VERSION "created by canmatrix"

NS_ :

BS_:

BU_: User ADM_PC_LL25 ADM_PC_BC25 ADM_PC_BP25 ADM_PC_BI25

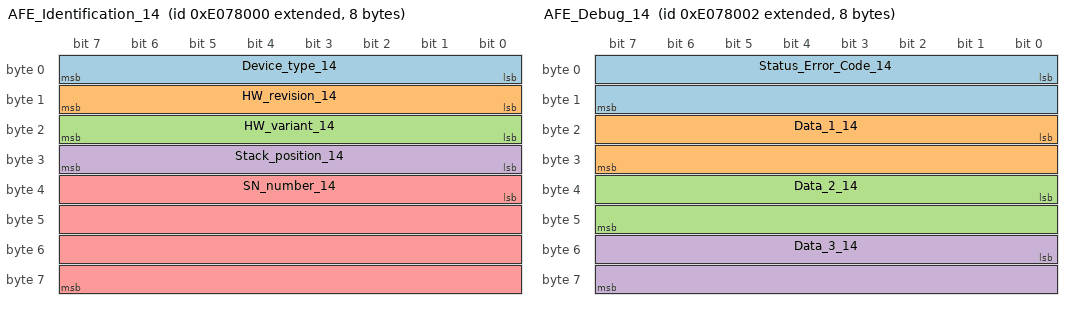
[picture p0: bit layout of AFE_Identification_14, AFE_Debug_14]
BO_ 2382856192 AFE_Identification_14: 8 ADM_PC_BP25
 SG_ Device_type_14 : 0|8@1+ (1,0) [0|255] "" Vector__XXX
 SG_ HW_revision_14 : 8|8@1+ (1,0) [0|255] "" Vector__XXX
 SG_ HW_variant_14 : 16|8@1+ (1,0) [0|255] "" Vector__XXX
 SG_ Stack_position_14 : 24|8@1+ (1,0) [0|255] "" Vector__XXX
 SG_ SN_number_14 : 32|32@1+ (1,0) [0|4294967295] "" Vector__XXX

BO_ 2382856193 AFE_FwInfo_14: 8 ADM_PC_BP25
 SG_ FW_info_mux_14 M : 56|8@1+ (1,0) [0|255] "" Vector__XXX
 SG_ FW_revision_0_14 m0 : 0|8@1+ (1,0) [0|255] "" Vector__XXX
 SG_ FW_revision_1_14 m0 : 8|8@1+ (1,0) [0|255] "" Vector__XXX
 SG_ FW_revision_2_14 m0 : 16|8@1+ (1,0) [0|255] "" Vector__XXX
 SG_ FW_revision_3_14 m0 : 24|8@1+ (1,0) [0|255] "" Vector__XXX
 SG_ FW_revision_4_14 m0 : 32|8@1+ (1,0) [0|255] "" Vector__XXX
 SG_ FW_revision_5_14 m0 : 40|8@1+ (1,0) [0|255] "" Vector__XXX
 SG_ FW_revision_6_14 m0 : 48|8@1+ (1,0) [0|255] "" Vector__XXX
 SG_ FW_revision_7_14 m1 : 0|8@1+ (1,0) [0|255] "" Vector__XXX
 SG_ FW_revision_8_14 m1 : 8|8@1+ (1,0) [0|255] "" Vector__XXX
 SG_ FW_revision_9_14 m1 : 16|8@1+ (1,0) [0|255] "" Vector__XXX
 SG_ FW_revision_10_14 m1 : 24|8@1+ (1,0) [0|255] "" Vector__XXX
 SG_ FW_revision_11_14 m1 : 32|8@1+ (1,0) [0|255] "" Vector__XXX
 SG_ FW_revision_12_14 m1 : 40|8@1+ (1,0) [0|255] "" Vector__XXX
 SG_ FW_revision_13_14 m1 : 48|8@1+ (1,0) [0|255] "" Vector__XXX
 SG_ FW_datecode_0_14 m2 : 0|8@1+ (1,0) [0|255] "" Vector__XXX
 SG_ FW_datecode_1_14 m2 : 8|8@1+ (1,0) [0|255] "" Vector__XXX
 SG_ FW_datecode_2_14 m2 : 16|8@1+ (1,0) [0|255] "" Vector__XXX
 SG_ FW_datecode_3_14 m2 : 24|8@1+ (1,0) [0|255] "" Vector__XXX
 SG_ FW_datecode_4_14 m2 : 32|8@1+ (1,0) [0|255] "" Vector__XXX
 SG_ FW_datecode_5_14 m2 : 40|8@1+ (1,0) [0|255] "" Vector__XXX
 SG_ FW_datecode_6_14 m2 : 48|8@1+ (1,0) [0|255] "" Vector__XXX
 SG_ FW_datecode_7_14 m3 : 0|8@1+ (1,0) [0|255] "" Vector__XXX
 SG_ FW_datecode_8_14 m3 : 8|8@1+ (1,0) [0|255] "" Vector__XXX
 SG_ FW_datecode_9_14 m3 : 16|8@1+ (1,0) [0|255] "" Vector__XXX
 SG_ FW_datecode_10_14 m3 : 24|8@1+ (1,0) [0|255] "" Vector__XXX
 SG_ FW_datecode_11_14 m3 : 32|8@1+ (1,0) [0|255] "" Vector__XXX
 SG_ FW_datecode_12_14 m3 : 40|8@1+ (1,0) [0|255] "" Vector__XXX
 SG_ FW_datecode_13_14 m3 : 48|8@1+ (1,0) [0|255] "" Vector__XXX

BO_ 2382856205 _AFE_Boot_FwInfo_14: 8 ADM_PC_BP25
 SG_ Boot_FW_info_mux_14 M : 56|8@1+ (1,0) [0|255] "" Vector__XXX
 SG_ FW_revision_0_14 m0 : 0|8@1+ (1,0) [0|255] "" Vector__XXX
 SG_ FW_revision_1_14 m0 : 8|8@1+ (1,0) [0|255] "" Vector__XXX
 SG_ FW_revision_2_14 m0 : 16|8@1+ (1,0) [0|255] "" Vector__XXX
 SG_ FW_revision_3_14 m0 : 24|8@1+ (1,0) [0|255] "" Vector__XXX
 SG_ FW_revision_4_14 m0 : 32|8@1+ (1,0) [0|255] "" Vector__XXX
 SG_ FW_revision_5_14 m0 : 40|8@1+ (1,0) [0|255] "" Vector__XXX
 SG_ FW_revision_6_14 m0 : 48|8@1+ (1,0) [0|255] "" Vector__XXX
 SG_ FW_revision_7_14 m1 : 0|8@1+ (1,0) [0|255] "" Vector__XXX
 SG_ FW_revision_8_14 m1 : 8|8@1+ (1,0) [0|255] "" Vector__XXX
 SG_ FW_revision_9_14 m1 : 16|8@1+ (1,0) [0|255] "" Vector__XXX
 SG_ FW_revision_10_14 m1 : 24|8@1+ (1,0) [0|255] "" Vector__XXX
 SG_ FW_revision_11_14 m1 : 32|8@1+ (1,0) [0|255] "" Vector__XXX
 SG_ FW_revision_12_14 m1 : 40|8@1+ (1,0) [0|255] "" Vector__XXX
 SG_ FW_revision_13_14 m1 : 48|8@1+ (1,0) [0|255] "" Vector__XXX
 SG_ FW_datecode_0_14 m2 : 0|8@1+ (1,0) [0|255] "" Vector__XXX
 SG_ FW_datecode_1_14 m2 : 8|8@1+ (1,0) [0|255] "" Vector__XXX
 SG_ FW_datecode_2_14 m2 : 16|8@1+ (1,0) [0|255] "" Vector__XXX
 SG_ FW_datecode_3_14 m2 : 24|8@1+ (1,0) [0|255] "" Vector__XXX
 SG_ FW_datecode_4_14 m2 : 32|8@1+ (1,0) [0|255] "" Vector__XXX
 SG_ FW_datecode_5_14 m2 : 40|8@1+ (1,0) [0|255] "" Vector__XXX
 SG_ FW_datecode_6_14 m2 : 48|8@1+ (1,0) [0|255] "" Vector__XXX
 SG_ FW_datecode_7_14 m3 : 0|8@1+ (1,0) [0|255] "" Vector__XXX
 SG_ FW_datecode_8_14 m3 : 8|8@1+ (1,0) [0|255] "" Vector__XXX
 SG_ FW_datecode_9_14 m3 : 16|8@1+ (1,0) [0|255] "" Vector__XXX
 SG_ FW_datecode_10_14 m3 : 24|8@1+ (1,0) [0|255] "" Vector__XXX
 SG_ FW_datecode_11_14 m3 : 32|8@1+ (1,0) [0|255] "" Vector__XXX
 SG_ FW_datecode_12_14 m3 : 40|8@1+ (1,0) [0|255] "" Vector__XXX
 SG_ FW_datecode_13_14 m3 : 48|8@1+ (1,0) [0|255] "" Vector__XXX

BO_ 2382856194 AFE_Debug_14: 8 ADM_PC_BP25
 SG_ Status_Error_Code_14 : 0|16@1+ (1,0) [0|65535] "" Vector__XXX
 SG_ Data_1_14 : 16|16@1+ (1,0) [0|65535] "" Vector__XXX
 SG_ Data_2_14 : 32|16@1+ (1,0) [0|65535] "" Vector__XXX
 SG_ Data_3_14 : 48|16@1+ (1,0) [0|65535] "" Vector__XXX

BO_ 2382856199 AFE_Status_14: 8 ADM_PC_BP25
 SG_ Running_14 : 0|1@1+ (1,0) [0|1] "" Vector__XXX
 SG_ PWM_14 : 1|1@1+ (1,0) [0|1] "" Vector__XXX
 SG_ Current_dc_loop_mode_14 : 2|1@1+ (1,0) [0|1] "" Vector__XXX
 SG_ Current_ac_loop_mode_14 : 3|1@1+ (1,0) [0|1] "" Vector__XXX
 SG_ Buck_14 : 5|1@1+ (1,0) [0|1] "" Vector__XXX
 SG_ Boost_14 : 6|1@1+ (1,0) [0|1] "" Vector__XXX
 SG_ Precharge_dc_buck_mode_14 : 7|1@1+ (1,0) [0|1] "" Vector__XXX
 SG_ Precharge_dc_boost_mode_14 : 8|1@1+ (1,0) [0|1] "" Vector__XXX
 SG_ Rectifier_3ph_14 : 9|1@1+ (1,0) [0|1] "" Vector__XXX
 SG_ Stack_mode_14 : 10|1@1+ (1,0) [0|1] "" Vector__XXX
 SG_ Master_14 : 11|1@1+ (1,0) [0|1] "" Vector__XXX
 SG_ Slave_14 : 12|1@1+ (1,0) [0|1] "" Vector__XXX
 SG_ Inverter_1ph_14 : 13|1@1+ (1,0) [0|1] "" Vector__XXX
 SG_ Boost_Neutral_14 : 14|1@1+ (1,0) [0|1] "" Vector__XXX
 SG_ Rectifier_1ph_14 : 15|1@1+ (1,0) [0|1] "" Vector__XXX
 SG_ Inverter_3ph_14 : 16|1@1+ (1,0) [0|1] "" Vector__XXX
 SG_ Ready_14 : 17|1@1+ (1,0) [0|1] "" Vector__XXX
 SG_ Inverter_1ph_Sync_14 : 18|1@1+ (1,0) [0|1] "" Vector__XXX
 SG_ Neutral_14 : 19|1@1+ (1,0) [0|1] "" Vector__XXX
 SG_ Rectifier_1ph_Buck_14 : 20|1@1+ (1,0) [0|1] "" Vector__XXX
 SG_ Inverter_1ph_Boost_14 : 21|1@1+ (1,0) [0|1] "" Vector__XXX
 SG_ Rectifier_distributed_14 : 22|1@1+ (1,0) [0|1] "" Vector__XXX
 SG_ MPPT_buck_14 : 23|1@1+ (1,0) [0|1] "" Vector__XXX
 SG_ MPPT_boost_14 : 24|1@1+ (1,0) [0|1] "" Vector__XXX
 SG_ Buck_2p_float_14 : 25|1@1+ (1,0) [0|1] "" Vector__XXX
 SG_ Inverter_1ph_Distributed_14 : 26|1@1+ (1,0) [0|1] "" Vector__XXX

BO_ 2382856198 AFE_Faults_14: 3 ADM_PC_BP25
 SG_ Protection_trip_internal_14 : 0|1@1+ (1,0) [0|1] "" Vector__XXX
 SG_ Protection_trip_external_14 : 1|1@1+ (1,0) [0|1] "" Vector__XXX
 SG_ Phase_U_overcurrent_14 : 2|1@1+ (1,0) [0|1] "" Vector__XXX
 SG_ Phase_U_overvoltage_14 : 3|1@1+ (1,0) [0|1] "" Vector__XXX
 SG_ Phase_U_undervoltage_14 : 4|1@1+ (1,0) [0|1] "" Vector__XXX
 SG_ Phase_V_overvoltage_14 : 5|1@1+ (1,0) [0|1] "" Vector__XXX
 SG_ Phase_V_undervoltage_14 : 6|1@1+ (1,0) [0|1] "" Vector__XXX
 SG_ Phase_V_overcurrent_14 : 7|1@1+ (1,0) [0|1] "" Vector__XXX
 SG_ Phase_W_overvoltage_14 : 8|1@1+ (1,0) [0|1] "" Vector__XXX
 SG_ Phase_W_undervoltage_14 : 9|1@1+ (1,0) [0|1] "" Vector__XXX
 SG_ Phase_W_overcurrent_14 : 10|1@1+ (1,0) [0|1] "" Vector__XXX
 SG_ DC_undervoltage_14 : 11|1@1+ (1,0) [0|1] "" Vector__XXX
 SG_ DC_overvoltage_14 : 12|1@1+ (1,0) [0|1] "" Vector__XXX
 SG_ MOSFET_overtemperature_14 : 13|1@1+ (1,0) [0|1] "" Vector__XXX
 SG_ Inductor_overtemperature_14 : 14|1@1+ (1,0) [0|1] "" Vector__XXX
 SG_ Keep_Alive_not_served_14 : 15|1@1+ (1,0) [0|1] "" Vector__XXX
 SG_ PLL_not_locked_14 : 16|1@1+ (1,0) [0|1] "" Vector__XXX
 SG_ NFO_14 : 20|1@1+ (1,0) [0|1] "" Vector__XXX
 SG_ Measurement_system_failure_14 : 21|1@1+ (1,0) [0|1] "" Vector__XXX
 SG_ EEPROM_failure_14 : 22|1@1+ (1,0) [0|1] "" Vector__XXX
 SG_ System_14 : 23|1@1+ (1,0) [0|1] "" Vector__XXX

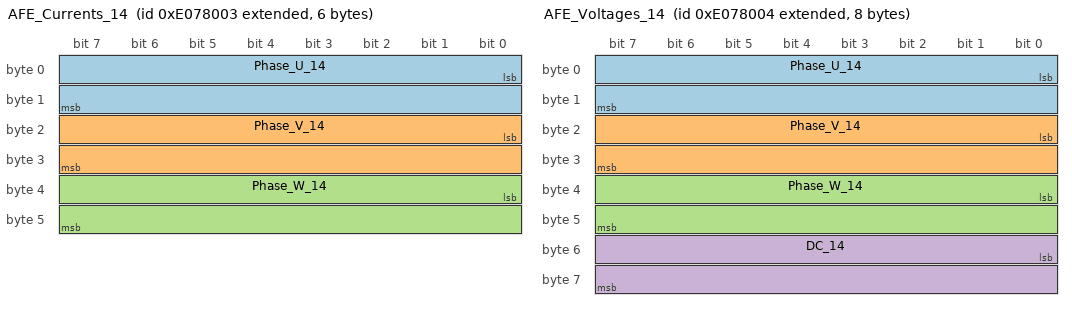
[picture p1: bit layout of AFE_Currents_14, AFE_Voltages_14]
BO_ 2382856195 AFE_Currents_14: 6 ADM_PC_BP25
 SG_ Phase_U_14 : 0|16@1- (0.01,0) [-327.68|327.67] "A" Vector__XXX
 SG_ Phase_V_14 : 16|16@1- (0.01,0) [-327.68|327.67] "A" Vector__XXX
 SG_ Phase_W_14 : 32|16@1- (0.01,0) [-327.68|327.67] "A" Vector__XXX

BO_ 2382856208 AFE_DC_Bus_current_14: 2 ADM_PC_BP25
 SG_ Bus_current_14 : 0|16@1- (0.01,0) [-327.68|327.67] "A" Vector__XXX

BO_ 2382856206 _AFE_Broadcast_14: 8 ADM_PC_BP25
 SG_ Diagnostics_Index_14 M : 56|8@1+ (1,0) [0|255] "" Vector__XXX
 SG_ Phase_U_14 m1 : 8|16@1- (0.01,0) [-327.68|327.67] "A" ADM_PC_BP25
 SG_ Phase_V_14 m1 : 24|16@1- (0.01,0) [-327.68|327.67] "A" ADM_PC_BP25
 SG_ Phase_W_14 m1 : 40|16@1- (0.01,0) [-327.68|327.67] "A" ADM_PC_BP25
 SG_ Stack_position_14 : 0|5@1+ (1,0) [0|31] "" ADM_PC_BP25
 SG_ Group_ID_14 : 5|3@1+ (1,0) [0|7] "" ADM_PC_BP25

BO_ 2382856196 AFE_Voltages_14: 8 ADM_PC_BP25
 SG_ Phase_U_14 : 0|16@1- (0.1,0) [-3276.8|3276.7] "V" Vector__XXX
 SG_ Phase_V_14 : 16|16@1- (0.1,0) [-3276.8|3276.7] "V" Vector__XXX
 SG_ Phase_W_14 : 32|16@1- (0.1,0) [-3276.8|3276.7] "V" Vector__XXX
 SG_ DC_14 : 48|16@1- (0.1,0) [-3276.8|3276.7] "V" Vector__XXX

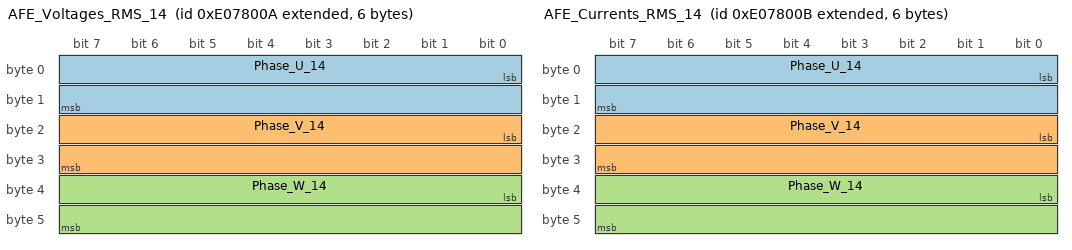
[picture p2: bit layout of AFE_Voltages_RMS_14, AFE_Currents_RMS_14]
BO_ 2382856202 AFE_Voltages_RMS_14: 6 ADM_PC_BP25
 SG_ Phase_U_14 : 0|16@1+ (0.1,0) [0|6553.5] "V" Vector__XXX
 SG_ Phase_V_14 : 16|16@1+ (0.1,0) [0|6553.5] "V" Vector__XXX
 SG_ Phase_W_14 : 32|16@1+ (0.1,0) [0|6553.5] "V" Vector__XXX

BO_ 2382856203 AFE_Currents_RMS_14: 6 ADM_PC_BP25
 SG_ Phase_U_14 : 0|16@1+ (0.01,0) [0.00|655.35] "A" Vector__XXX
 SG_ Phase_V_14 : 16|16@1+ (0.01,0) [0.00|655.35] "A" Vector__XXX
 SG_ Phase_W_14 : 32|16@1+ (0.01,0) [0.00|655.35] "A" Vector__XXX

BO_ 2382856204 AFE_Mains_14: 4 ADM_PC_BP25
 SG_ Frequency_14 : 0|16@1+ (0.01,0) [0.00|655.35] "Hz" Vector__XXX
 SG_ Phase_14 : 16|16@1- (0.1,0) [-3276.8|3276.7] "Deg." Vector__XXX

BO_ 2382856197 AFE_Temperatures_14: 4 ADM_PC_BP25
 SG_ Temp_Bridge_14 : 0|16@1- (0.01,0) [-327.68|327.67] "°C" Vector__XXX
 SG_ Temp_Inductors_14 : 16|16@1- (0.01,0) [-327.68|327.67] "°C" Vector__XXX

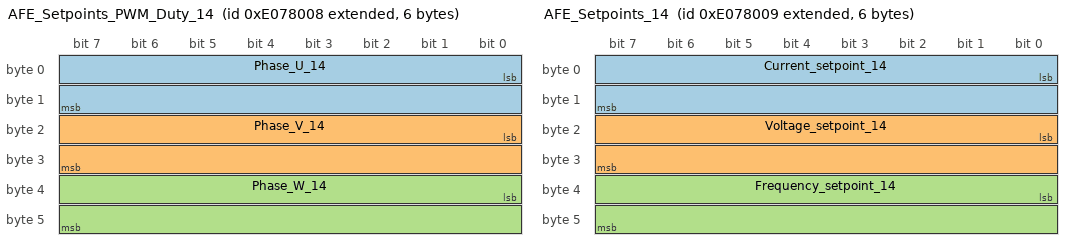
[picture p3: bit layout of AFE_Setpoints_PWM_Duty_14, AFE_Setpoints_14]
BO_ 2382856200 AFE_Setpoints_PWM_Duty_14: 6 ADM_PC_BP25
 SG_ Phase_U_14 : 0|16@1+ (0.001525902,0) [0E-009|99.999987570] "%" Vector__XXX
 SG_ Phase_V_14 : 16|16@1+ (0.001525902,0) [0E-009|99.999987570] "%" Vector__XXX
 SG_ Phase_W_14 : 32|16@1+ (0.001525902,0) [0E-009|99.999987570] "%" Vector__XXX

BO_ 2382856201 AFE_Setpoints_14: 6 ADM_PC_BP25
 SG_ Current_setpoint_14 : 0|16@1- (0.01,0) [-327.68|327.67] "A" Vector__XXX
 SG_ Voltage_setpoint_14 : 16|16@1+ (0.1,0) [0|6553.5] "V" Vector__XXX
 SG_ Frequency_setpoint_14 : 32|16@1+ (0.01,0) [0.00|655.35] "Hz" Vector__XXX

BO_ 2382823520 AFE_Keep_Alive_14: 1 User
 SG_ Keep_Alive_Enable_14 : 0|1@1+ (1,0) [0|1] "" ADM_PC_BP25

BO_ 2382823488 AFE_Mode_Control_14: 8 User
 SG_ Converter_ON_14 : 0|1@1+ (1,0) [0|1] "" ADM_PC_BP25
 SG_ PWM_ON_14 : 1|1@1+ (1,0) [0|1] "" ADM_PC_BP25
 SG_ DC_Current_feedback_ON_14 : 2|1@1+ (1,0) [0|1] "" ADM_PC_BP25
 SG_ AC_Current_feedback_ON_14 : 3|1@1+ (1,0) [0|1] "" ADM_PC_BP25
 SG_ Buck_ON_14 : 5|1@1+ (1,0) [0|1] "" ADM_PC_BP25
 SG_ Boost_ON_14 : 6|1@1+ (1,0) [0|1] "" ADM_PC_BP25
 SG_ Rectifier_3ph_ON_14 : 9|1@1+ (1,0) [0|1] "" ADM_PC_BP25
 SG_ Inverter_1ph_ON_14 : 10|1@1+ (1,0) [0|1] "" ADM_PC_BP25
 SG_ Rectifier_1ph_ON_14 : 11|1@1+ (1,0) [0|1] "" ADM_PC_BP25
 SG_ Boost_Neutral_ON_14 : 12|1@1+ (1,0) [0|1] "" ADM_PC_BP25
 SG_ Inverter_3ph_ON_14 : 13|1@1+ (1,0) [0|1] "" ADM_PC_BP25
 SG_ Inverter_1ph_Sync_ON_14 : 14|1@1+ (1,0) [0|1] "" ADM_PC_BP25
 SG_ Neutral_ON_14 : 15|1@1+ (1,0) [0|1] "" ADM_PC_BP25
 SG_ Rectifier_1ph_Buck_ON_14 : 16|1@1+ (1,0) [0|1] "" ADM_PC_BP25
 SG_ Inverter_1ph_Boost_ON_14 : 17|1@1+ (1,0) [0|1] "" ADM_PC_BP25
 SG_ Rectifier_Distributed_ON_14 : 18|1@1+ (1,0) [0|1] "" ADM_PC_BP25
 SG_ MPPT_buck_ON_14 : 19|1@1+ (1,0) [0|1] "" ADM_PC_BP25
 SG_ MPPT_boost_ON_14 : 20|1@1+ (1,0) [0|1] "" ADM_PC_BP25
 SG_ Buck_2p_float_ON_14 : 21|1@1+ (1,0) [0|1] "" ADM_PC_BP25
 SG_ Inverter_1ph_Distributed_ON_14 : 22|1@1+ (1,0) [0|1] "" ADM_PC_BP25

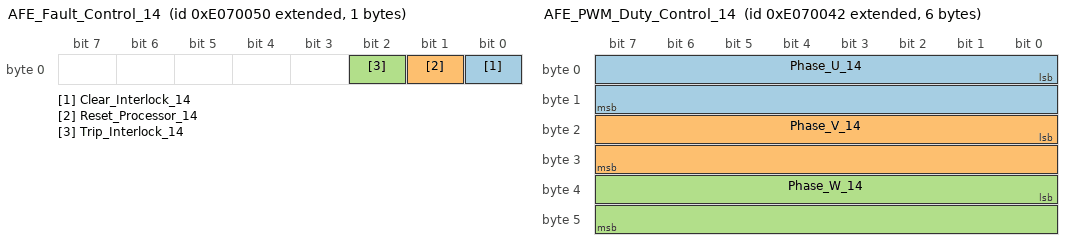
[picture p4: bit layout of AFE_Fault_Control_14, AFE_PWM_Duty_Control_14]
BO_ 2382823504 AFE_Fault_Control_14: 1 User
 SG_ Clear_Interlock_14 : 0|1@1+ (1,0) [0|1] "" ADM_PC_BP25
 SG_ Reset_Processor_14 : 1|1@1+ (1,0) [0|1] "" ADM_PC_BP25
 SG_ Trip_Interlock_14 : 2|1@1+ (1,0) [0|1] "" ADM_PC_BP25

BO_ 2382823489 AFE_Reactive_Current_Setpoint_Co: 2 User
 SG_ Reactive_current_setpoint_14 : 0|16@1- (0.01,0) [-150|150] "A" ADM_PC_BP25

BO_ 2382823490 AFE_PWM_Duty_Control_14: 6 User
 SG_ Phase_U_14 : 0|16@1+ (0.001525902,0) [0E-009|99.999987570] "%" ADM_PC_BP25
 SG_ Phase_V_14 : 16|16@1+ (0.001525902,0) [0E-009|99.999987570] "%" ADM_PC_BP25
 SG_ Phase_W_14 : 32|16@1+ (0.001525902,0) [0E-009|99.999987570] "%" ADM_PC_BP25

BO_ 2382823491 AFE_Current_Setpoint_Control_14: 2 User
 SG_ Current_setpoint_14 : 0|16@1- (0.01,0) [-150|150] "A" ADM_PC_BP25

BO_ 2382823492 AFE_Voltage_Setpoint_Control_14: 2 User
 SG_ Voltage_setpoint_14 : 0|16@1+ (0.1,0) [0|1500] "V" ADM_PC_BP25

BO_ 2382823496 AFE_Frequency_Setpoint_Control_1: 2 User
 SG_ Frequency_setpoint_14 : 0|16@1+ (0.01,0) [40|70] "Hz" ADM_PC_BP25

BO_ 2382823497 AFE_Phase_Setpoint_Control_14: 2 User
 SG_ Phase_setpoint_14 : 0|16@1+ (1,0) [0|360] "deg" ADM_PC_BP25

BO_ 2382823536 AFE_Rectifier_Setpoint_Control_1: 8 User
 SG_ Voltage_setpoint_2_14 : 0|16@1+ (0.1,0) [0|1500] "V" ADM_PC_BP25
 SG_ Current_setpoint_2_14 : 16|16@1- (0.01,0) [-150|150] "A" ADM_PC_BP25

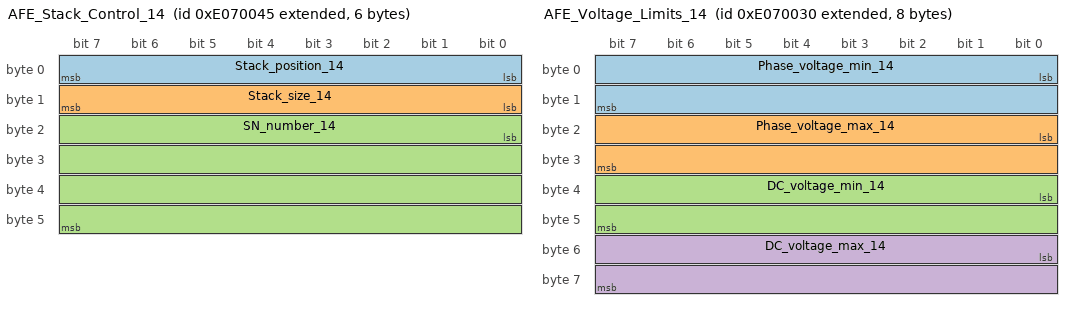
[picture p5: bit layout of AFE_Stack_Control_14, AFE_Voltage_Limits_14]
BO_ 2382823493 AFE_Stack_Control_14: 6 User
 SG_ Stack_position_14 : 0|8@1+ (1,0) [0|255] "" ADM_PC_BP25
 SG_ Stack_size_14 : 8|8@1+ (1,0) [0|255] "" ADM_PC_BP25
 SG_ SN_number_14 : 16|32@1+ (1,0) [0|4294967295] "" ADM_PC_BP25

BO_ 2382823472 AFE_Voltage_Limits_14: 8 User
 SG_ Phase_voltage_min_14 : 0|16@1- (0.1,0) [0|3276.7] "V" ADM_PC_BP25
 SG_ Phase_voltage_max_14 : 16|16@1- (0.1,0) [-3276.8|850] "V" ADM_PC_BP25
 SG_ DC_voltage_min_14 : 32|16@1- (0.1,0) [0|3276.7] "V" ADM_PC_BP25
 SG_ DC_voltage_max_14 : 48|16@1- (0.1,0) [-3276.8|850] "V" ADM_PC_BP25

BO_ 2382823473 AFE_Current_Limits_14: 4 User
 SG_ Phase_current_min_14 : 0|16@1- (0.01,0) [-60|60] "A" ADM_PC_BP25
 SG_ Phase_current_max_14 : 16|16@1- (0.01,0) [-60|60] "A" ADM_PC_BP25

BO_ 2382823500 AFE_Group_Control_14: 1 User
 SG_ Group_ID_14 : 0|8@1+ (1,0) [0|255] "" ADM_PC_BP25

BO_ 2382856207 AFE_Group_Info_14: 1 ADM_PC_BP25
 SG_ Group_ID_14 : 0|8@1+ (1,0) [0|255] "" Vector__XXX

BO_ 2382823521 AFE_System_Flags_Control_14: 8 User
 SG_ Factory_mode_14 : 0|1@1+ (1,0) [0|1] "" ADM_PC_BP25
 SG_ Silent_CAN_mode_14 : 1|1@1+ (1,0) [0|1] "" ADM_PC_BP25

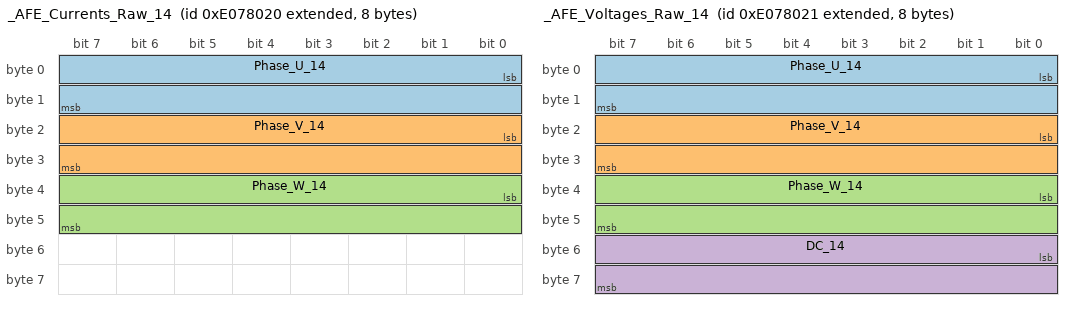
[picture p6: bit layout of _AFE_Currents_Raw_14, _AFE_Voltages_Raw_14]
BO_ 2382856224 _AFE_Currents_Raw_14: 8 ADM_PC_BP25
 SG_ Phase_U_14 : 0|16@1- (1,0) [-32768|32767] "" Vector__XXX
 SG_ Phase_V_14 : 16|16@1- (1,0) [-32768|32767] "" Vector__XXX
 SG_ Phase_W_14 : 32|16@1- (1,0) [-32768|32767] "" Vector__XXX

BO_ 2382856225 _AFE_Voltages_Raw_14: 8 ADM_PC_BP25
 SG_ Phase_U_14 : 0|16@1- (1,0) [-32768|32767] "" Vector__XXX
 SG_ Phase_V_14 : 16|16@1- (1,0) [-32768|32767] "" Vector__XXX
 SG_ Phase_W_14 : 32|16@1- (1,0) [-32768|32767] "" Vector__XXX
 SG_ DC_14 : 48|16@1- (1,0) [-32768|32767] "" Vector__XXX

BO_ 2382823498 _AFE_ADC_Calibration_Mode_14: 1 User
 SG_ Calibration_Index_14 M : 2|5@1+ (1,0) [0|31] "" Vector__XXX
 SG_ Current_U_14 m1 : 0|2@1+ (1,0) [0|3] "" ADM_PC_BP25
 SG_ Current_V_14 m2 : 0|2@1+ (1,0) [0|3] "" ADM_PC_BP25
 SG_ Current_W_14 m3 : 0|2@1+ (1,0) [0|3] "" ADM_PC_BP25
 SG_ Voltage_U_14 m4 : 0|2@1+ (1,0) [0|3] "" ADM_PC_BP25
 SG_ Voltage_V_14 m5 : 0|2@1+ (1,0) [0|3] "" ADM_PC_BP25
 SG_ Voltage_W_14 m6 : 0|2@1+ (1,0) [0|3] "" ADM_PC_BP25
 SG_ Voltage_DC_14 m7 : 0|2@1+ (1,0) [0|3] "" ADM_PC_BP25
 SG_ start_14 : 7|1@1+ (1,0) [0|1] "" ADM_PC_BP25

BO_ 2382823499 _AFE_ADC_Calibration_Setpoint_14: 3 User
 SG_ Calibration_Index_14 M : 16|5@1+ (1,0) [0|31] "" Vector__XXX
 SG_ Current_U_14 m1 : 0|16@1- (0.01,0) [-100|100] "A" ADM_PC_BP25
 SG_ Current_V_14 m2 : 0|16@1- (0.01,0) [-100|100] "A" ADM_PC_BP25
 SG_ Current_W_14 m3 : 0|16@1- (0.01,0) [-100|100] "A" ADM_PC_BP25
 SG_ Voltage_U_14 m4 : 0|16@1+ (0.1,0) [0|1500] "V" ADM_PC_BP25
 SG_ Voltage_V_14 m5 : 0|16@1+ (0.1,0) [0|1500] "V" ADM_PC_BP25
 SG_ Voltage_W_14 m6 : 0|16@1+ (0.1,0) [0|1500] "V" ADM_PC_BP25
 SG_ Voltage_DC_14 m7 : 0|16@1+ (0.1,0) [0|1500] "V" ADM_PC_BP25
 SG_ point_14 : 21|3@1+ (1,0) [0|7] "" ADM_PC_BP25

BO_ 2382823494 _AFE_Calibration_Offset_Update_1: 6 User
 SG_ Calibration_Index_14 M : 16|16@1+ (1,0) [0|65535] "" Vector__XXX
 SG_ Current_U_14 m0 : 0|16@1- (1,0) [-32768|32767] "ADC Counts" ADM_PC_BP25
 SG_ Current_V_14 m1 : 0|16@1- (1,0) [-32768|32767] "ADC Counts" ADM_PC_BP25
 SG_ Current_W_14 m2 : 0|16@1- (1,0) [-32768|32767] "ADC Counts" ADM_PC_BP25
 SG_ Voltage_U_14 m3 : 0|16@1- (1,0) [-32768|32767] "ADC Counts" ADM_PC_BP25
 SG_ Voltage_V_14 m4 : 0|16@1- (1,0) [-32768|32767] "ADC Counts" ADM_PC_BP25
 SG_ Voltage_W_14 m5 : 0|16@1- (1,0) [-32768|32767] "ADC Counts" ADM_PC_BP25
 SG_ Voltage_DC_14 m6 : 0|16@1- (1,0) [-32768|32767] "ADC Counts" ADM_PC_BP25
 SG_ CRC_14 : 32|16@1+ (1,0) [0|65535] "-" ADM_PC_BP25

BO_ 2382823495 _AFE_Calibration_Scale_Update_14: 6 User
 SG_ Calibration_Index_14 M : 16|16@1+ (1,0) [0|65535] "" Vector__XXX
 SG_ Current_U_14 m0 : 0|16@1- (0.0000152587890625,0) [-0.5000000000000000|0.4999847412109375] "scale = 1.0 + value" ADM_PC_BP25
 SG_ Current_V_14 m1 : 0|16@1- (0.0000152587890625,0) [-0.5000000000000000|0.4999847412109375] "scale = 1.0 + value" ADM_PC_BP25
 SG_ Current_W_14 m2 : 0|16@1- (0.0000152587890625,0) [-0.5000000000000000|0.4999847412109375] "scale = 1.0 + value" ADM_PC_BP25
 SG_ Voltage_U_14 m3 : 0|16@1- (0.0000152587890625,0) [-0.5000000000000000|0.4999847412109375] "scale = 1.0 + value" ADM_PC_BP25
 SG_ Voltage_V_14 m4 : 0|16@1- (0.0000152587890625,0) [-0.5000000000000000|0.4999847412109375] "scale = 1.0 + value" ADM_PC_BP25
 SG_ Voltage_W_14 m5 : 0|16@1- (0.0000152587890625,0) [-0.5000000000000000|0.4999847412109375] "scale = 1.0 + value" ADM_PC_BP25
 SG_ Voltage_DC_14 m6 : 0|16@1- (0.0000152587890625,0) [-0.5000000000000000|0.4999847412109375] "scale = 1.0 + value" ADM_PC_BP25
 SG_ CRC_14 : 32|16@1+ (1,0) [0|65535] "-" ADM_PC_BP25

BO_ 2382856273 _AFE_Calibration_Adc_Scale_14: 6 ADM_PC_BP25
 SG_ Adc_Index_14 M : 32|16@1+ (1,0) [0|65535] "" Vector__XXX
 SG_ Current_U_14 m0 : 0|32@1+ (1,0) [0|4294967295] "1 / adc_bins" User
 SG_ Current_V_14 m1 : 0|32@1+ (1,0) [0|4294967295] "1 / adc_bins" User
 SG_ Current_W_14 m2 : 0|32@1+ (1,0) [0|4294967295] "1 / adc_bins" User
 SG_ Voltage_U_14 m3 : 0|32@1+ (1,0) [0|4294967295] "1 / adc_bins" User
 SG_ Voltage_V_14 m4 : 0|32@1+ (1,0) [0|4294967295] "1 / adc_bins" User
 SG_ Voltage_W_14 m5 : 0|32@1+ (1,0) [0|4294967295] "1 / adc_bins" User
 SG_ Voltage_DC_14 m6 : 0|32@1+ (1,0) [0|4294967295] "1 / adc_bins" User

BO_ 2382856274 _AFE_Calibration_Adc_Fs_14: 6 ADM_PC_BP25
 SG_ Adc_Index_14 M : 32|16@1+ (1,0) [0|65535] "" Vector__XXX
 SG_ Current_U_14 m0 : 0|32@1+ (1,0) [0|4294967295] "Fullscale" User
 SG_ Current_V_14 m1 : 0|32@1+ (1,0) [0|4294967295] "Fullscale" User
 SG_ Current_W_14 m2 : 0|32@1+ (1,0) [0|4294967295] "Fullscale" User
 SG_ Voltage_U_14 m3 : 0|32@1+ (1,0) [0|4294967295] "Fullscale" User
 SG_ Voltage_V_14 m4 : 0|32@1+ (1,0) [0|4294967295] "Fullscale" User
 SG_ Voltage_W_14 m5 : 0|32@1+ (1,0) [0|4294967295] "Fullscale" User
 SG_ Voltage_DC_14 m6 : 0|32@1+ (1,0) [0|4294967295] "Fullscale" User

BO_ 2382856275 _AFE_Calibration_Adc_Offset_14: 4 ADM_PC_BP25
 SG_ Adc_Index_14 M : 16|16@1+ (1,0) [0|65535] "" Vector__XXX
 SG_ Current_U_14 m0 : 0|16@1- (1,0) [-32768|32767] "-" User
 SG_ Current_V_14 m1 : 0|16@1- (1,0) [-32768|32767] "-" User
 SG_ Current_W_14 m2 : 0|16@1- (1,0) [-32768|32767] "-" User
 SG_ Voltage_U_14 m3 : 0|16@1- (1,0) [-32768|32767] "-" User
 SG_ Voltage_V_14 m4 : 0|16@1- (1,0) [-32768|32767] "-" User
 SG_ Voltage_W_14 m5 : 0|16@1- (1,0) [-32768|32767] "-" User
 SG_ Voltage_DC_14 m6 : 0|16@1- (1,0) [-32768|32767] "-" User

BO_ 2382856276 _AFE_Calibration_Adc_Gain_14: 4 ADM_PC_BP25
 SG_ Adc_Index_14 M : 16|16@1+ (1,0) [0|65535] "" Vector__XXX
 SG_ Current_U_14 m0 : 0|16@1- (1,0) [-32768|32767] "-" User
 SG_ Current_V_14 m1 : 0|16@1- (1,0) [-32768|32767] "-" User
 SG_ Current_W_14 m2 : 0|16@1- (1,0) [-32768|32767] "-" User
 SG_ Voltage_U_14 m3 : 0|16@1- (1,0) [-32768|32767] "-" User
 SG_ Voltage_V_14 m4 : 0|16@1- (1,0) [-32768|32767] "-" User
 SG_ Voltage_W_14 m5 : 0|16@1- (1,0) [-32768|32767] "-" User
 SG_ Voltage_DC_14 m6 : 0|16@1- (1,0) [-32768|32767] "-" User

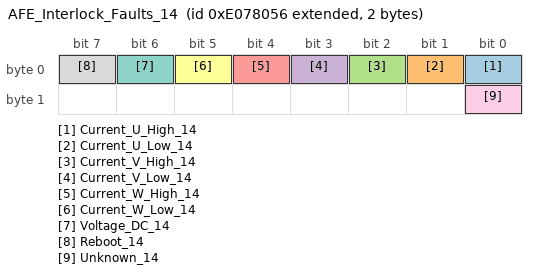
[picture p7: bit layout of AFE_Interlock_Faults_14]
BO_ 2382856278 AFE_Interlock_Faults_14: 2 ADM_PC_BP25
 SG_ Current_U_High_14 : 0|1@1+ (1,0) [0|1] "" Vector__XXX
 SG_ Current_U_Low_14 : 1|1@1+ (1,0) [0|1] "" Vector__XXX
 SG_ Current_V_High_14 : 2|1@1+ (1,0) [0|1] "" Vector__XXX
 SG_ Current_V_Low_14 : 3|1@1+ (1,0) [0|1] "" Vector__XXX
 SG_ Current_W_High_14 : 4|1@1+ (1,0) [0|1] "" Vector__XXX
 SG_ Current_W_Low_14 : 5|1@1+ (1,0) [0|1] "" Vector__XXX
 SG_ Voltage_DC_14 : 6|1@1+ (1,0) [0|1] "" Vector__XXX
 SG_ Reboot_14 : 7|1@1+ (1,0) [0|1] "" Vector__XXX
 SG_ Unknown_14 : 8|1@1+ (1,0) [0|1] "" Vector__XXX

BO_TX_BU_ 2382823488 : User,ADM_PC_LL25,ADM_PC_BC25,ADM_PC_BI25;
BO_TX_BU_ 2382823491 : User,ADM_PC_LL25,ADM_PC_BC25,ADM_PC_BI25;
BO_TX_BU_ 2382823492 : User,ADM_PC_LL25,ADM_PC_BC25,ADM_PC_BI25;
CM_ BO_ 2382856192  "Identification of the device";
CM_ BO_ 2382856193  "Git revision of the DSP firmware";
CM_ BO_ 2382856205  "Git revision of the bootloader firmware.";
CM_ BO_ 2382856194  "Values for debugging of HW/SW problems";
CM_ BO_ 2382856199  "Status bitfield";
CM_ BO_ 2382856198  "Fault bitfield";
CM_ BO_ 2382856195  "Current of phases U, V, W";
CM_ BO_ 2382856208  "Current of of the DC Bus";
CM_ BO_ 2382856206  "All AFEs will listen to this message";
CM_ BO_ 2382856203  "RMS Current of phases U, V, W";
CM_ BO_ 2382856204  "Three-Phase mains health (frequency, phase...)";
CM_ BO_ 2382856197  "Readouts of the module temperature sensors";
CM_ BO_ 2382856200  "Setpoints";
CM_ BO_ 2382856201  "Setpoints";
CM_ BO_ 2382823520  "Keep alive ping message. ";
CM_ BO_ 2382823488  "Operation Mode control: sets the converter operation mode";
CM_ BO_ 2382823504  "Fault Control: actions to clear faults and reset the system";
CM_ BO_ 2382823489  "Reactive power setpoint control.";
CM_ BO_ 2382823490  "PWM duty cycle control";
CM_ BO_ 2382823491  "Current setpoint control";
CM_ BO_ 2382823492  "Voltage setpoint control";
CM_ BO_ 2382823496  "Frequency setpoint control";
CM_ BO_ 2382823497  "Phase setpoint control";
CM_ BO_ 2382823536  "Additional voltage and current setpoints in single-phase rectifier and inverter control modes.";
CM_ BO_ 2382823493  "PFC stack control";
CM_ BO_ 2382823472  "Set the input and output voltage limits (minimum and maximum)";
CM_ BO_ 2382823473  "Set the output current limits (mminimum and maximum)";
CM_ BO_ 2382823500  "Set the Group ID of the device";
CM_ BO_ 2382856207  "Contains the Group ID of the device";
CM_ BO_ 2382823521  "Control the system flags";
CM_ BO_ 2382856224  "Current of phases A and B";
CM_ BO_ 2382856225  "Current of phases A and B";
CM_ BO_ 2382823498  "Automatic ADC calibration.";
CM_ BO_ 2382823499  "Setpoint for automatic ADC calibration.";
CM_ BO_ 2382823494  "Update of the calibration table for offsets.";
CM_ BO_ 2382823495  "Update of the calibration table for scales.";
CM_ BO_ 2382856273  "
                Adc scale (resolution) value of readouts.
            ";
CM_ BO_ 2382856274  "
                Adc fullscale value of readouts.
            ";
CM_ BO_ 2382856275  "
                Readout of ADC calibration data (offset) from EEPROM.
            ";
CM_ BO_ 2382856276  "
                Readout of ADC calibration data (gain) from EEPROM.
            ";
CM_ BO_ 2382856278  "Fault bitfield";

CM_ SG_ 2382856192 Device_type_14 "The device identification field, uniquely identifies the sender in the network";
CM_ SG_ 2382856192 HW_revision_14 "The hardware revision number";
CM_ SG_ 2382856192 HW_variant_14 "The DSP firmware revision number";
CM_ SG_ 2382856192 Stack_position_14 "Position of the module within the stack";
CM_ SG_ 2382856192 SN_number_14 "Unique module serial number";
CM_ SG_ 2382856193 FW_revision_0_14 "Character 0";
CM_ SG_ 2382856193 FW_revision_1_14 "Character 1";
CM_ SG_ 2382856193 FW_revision_2_14 "Character 2";
CM_ SG_ 2382856193 FW_revision_3_14 "Character 3";
CM_ SG_ 2382856193 FW_revision_4_14 "Character 3";
CM_ SG_ 2382856193 FW_revision_5_14 "Character 3";
CM_ SG_ 2382856193 FW_revision_6_14 "Character 3";
CM_ SG_ 2382856193 FW_revision_7_14 "Character 7";
CM_ SG_ 2382856193 FW_revision_8_14 "Character 8";
CM_ SG_ 2382856193 FW_revision_9_14 "Character 9";
CM_ SG_ 2382856193 FW_revision_10_14 "Character 10";
CM_ SG_ 2382856193 FW_revision_11_14 "Character 11";
CM_ SG_ 2382856193 FW_revision_12_14 "Character 12";
CM_ SG_ 2382856193 FW_revision_13_14 "Character 13";
CM_ SG_ 2382856193 FW_datecode_0_14 "Character 0";
CM_ SG_ 2382856193 FW_datecode_1_14 "Character 1";
CM_ SG_ 2382856193 FW_datecode_2_14 "Character 2";
CM_ SG_ 2382856193 FW_datecode_3_14 "Character 3";
CM_ SG_ 2382856193 FW_datecode_4_14 "Character 3";
CM_ SG_ 2382856193 FW_datecode_5_14 "Character 3";
CM_ SG_ 2382856193 FW_datecode_6_14 "Character 3";
CM_ SG_ 2382856193 FW_datecode_7_14 "Character 7";
CM_ SG_ 2382856193 FW_datecode_8_14 "Character 8";
CM_ SG_ 2382856193 FW_datecode_9_14 "Character 9";
CM_ SG_ 2382856193 FW_datecode_10_14 "Character 10";
CM_ SG_ 2382856193 FW_datecode_11_14 "Character 11";
CM_ SG_ 2382856193 FW_datecode_12_14 "Character 12";
CM_ SG_ 2382856193 FW_datecode_13_14 "Character 13";
CM_ SG_ 2382856205 FW_revision_0_14 "Character 0";
CM_ SG_ 2382856205 FW_revision_1_14 "Character 1";
CM_ SG_ 2382856205 FW_revision_2_14 "Character 2";
CM_ SG_ 2382856205 FW_revision_3_14 "Character 3";
CM_ SG_ 2382856205 FW_revision_4_14 "Character 3";
CM_ SG_ 2382856205 FW_revision_5_14 "Character 3";
CM_ SG_ 2382856205 FW_revision_6_14 "Character 3";
CM_ SG_ 2382856205 FW_revision_7_14 "Character 7";
CM_ SG_ 2382856205 FW_revision_8_14 "Character 8";
CM_ SG_ 2382856205 FW_revision_9_14 "Character 9";
CM_ SG_ 2382856205 FW_revision_10_14 "Character 10";
CM_ SG_ 2382856205 FW_revision_11_14 "Character 11";
CM_ SG_ 2382856205 FW_revision_12_14 "Character 12";
CM_ SG_ 2382856205 FW_revision_13_14 "Character 13";
CM_ SG_ 2382856205 FW_datecode_0_14 "Character 0";
CM_ SG_ 2382856205 FW_datecode_1_14 "Character 1";
CM_ SG_ 2382856205 FW_datecode_2_14 "Character 2";
CM_ SG_ 2382856205 FW_datecode_3_14 "Character 3";
CM_ SG_ 2382856205 FW_datecode_4_14 "Character 3";
CM_ SG_ 2382856205 FW_datecode_5_14 "Character 3";
CM_ SG_ 2382856205 FW_datecode_6_14 "Character 3";
CM_ SG_ 2382856205 FW_datecode_7_14 "Character 7";
CM_ SG_ 2382856205 FW_datecode_8_14 "Character 8";
CM_ SG_ 2382856205 FW_datecode_9_14 "Character 9";
CM_ SG_ 2382856205 FW_datecode_10_14 "Character 10";
CM_ SG_ 2382856205 FW_datecode_11_14 "Character 11";
CM_ SG_ 2382856205 FW_datecode_12_14 "Character 12";
CM_ SG_ 2382856205 FW_datecode_13_14 "Character 13";
CM_ SG_ 2382856194 Status_Error_Code_14 "Main status / error code as defined in errno/errno.h";
CM_ SG_ 2382856194 Data_1_14 "Additional information for the error/status";
CM_ SG_ 2382856194 Data_2_14 "Additional information for the error/status";
CM_ SG_ 2382856194 Data_3_14 "Additional information for the error/status";
CM_ SG_ 2382856199 Running_14 "Indicates if converter is running.";
CM_ SG_ 2382856199 PWM_14 "Indicates if converter is in PWM control mode.";
CM_ SG_ 2382856199 Current_dc_loop_mode_14 "Indicates if the current DC loop is enabled.";
CM_ SG_ 2382856199 Current_ac_loop_mode_14 "Indicates if the current AC loop is enabled.";
CM_ SG_ 2382856199 Buck_14 "Indicates if converter is in buck control mode.";
CM_ SG_ 2382856199 Boost_14 "Indicates if converter is in boost control mode.";
CM_ SG_ 2382856199 Precharge_dc_buck_mode_14 "Indicates if the precharge DC mode is enabled - buck direction.";
CM_ SG_ 2382856199 Precharge_dc_boost_mode_14 "Indicates if the precharge DC mode is enabled - boost direction.";
CM_ SG_ 2382856199 Rectifier_3ph_14 "Indicates if converter is in three-phase rectifier control mode.";
CM_ SG_ 2382856199 Stack_mode_14 "Indicates if converter is operating in stack mode.";
CM_ SG_ 2382856199 Master_14 "Indicates if converter is master in the stack.";
CM_ SG_ 2382856199 Slave_14 "Indicates if converter is slave in the stack.";
CM_ SG_ 2382856199 Inverter_1ph_14 "Indicates if converter is in single-phase inverter control mode.";
CM_ SG_ 2382856199 Boost_Neutral_14 "Indicates if converter is in boost control mode with neutral generation.";
CM_ SG_ 2382856199 Rectifier_1ph_14 "Indicates if converter is in single-phase rectifier control mode.";
CM_ SG_ 2382856199 Inverter_3ph_14 "Indicates if converter is in three-phase inverter control mode.";
CM_ SG_ 2382856199 Ready_14 "Indicates if converter is ready for operation.";
CM_ SG_ 2382856199 Inverter_1ph_Sync_14 "Single-phase inverter control mode with phase synchronization.";
CM_ SG_ 2382856199 Neutral_14 "Open-loop neutral generation.";
CM_ SG_ 2382856199 Rectifier_1ph_Buck_14 "Single-phase rectifier with buck on one leg.";
CM_ SG_ 2382856199 Inverter_1ph_Boost_14 "Single-phase inverter with boost on one leg.";
CM_ SG_ 2382856199 Rectifier_distributed_14 "Not available at the moment";
CM_ SG_ 2382856199 MPPT_buck_14 "Not available at the moment";
CM_ SG_ 2382856199 MPPT_boost_14 "Not available at the moment";
CM_ SG_ 2382856199 Buck_2p_float_14 "Buck in phases L1 and L2. Phase L3 is left floating (high impedance)";
CM_ SG_ 2382856199 Inverter_1ph_Distributed_14 "Single-phase inverter mode  distributed";
CM_ SG_ 2382856198 Protection_trip_internal_14 "This flagg is asserted if the interlock is open due to an internal fault condition (self-protection)";
CM_ SG_ 2382856198 Protection_trip_external_14 "This flag is asserted if the interlock is open due to an external condition received in the module.";
CM_ SG_ 2382856198 Phase_U_overcurrent_14 "Indicates an overcurrent event on Phase U. The overcurrent event is triggered when the measured phase current is over the programmed current limit.";
CM_ SG_ 2382856198 Phase_U_overvoltage_14 "Indicates an overvoltage event on Phase U. The overvoltage event is triggered when the measured phase voltage is over the programmed voltage limit.";
CM_ SG_ 2382856198 Phase_U_undervoltage_14 "Indicates an undervoltage event on Phase U. The overvoltage event is triggered when the measured phase voltage is over the programmed voltage limit.";
CM_ SG_ 2382856198 Phase_V_overvoltage_14 "Indicates an overvoltage event on Phase V. The overvoltage event is triggered when the measured phase voltage is over the programmed voltage limit.";
CM_ SG_ 2382856198 Phase_V_undervoltage_14 "Indicates an undervoltage event on Phase U. The overvoltage event is triggered when the measured phase voltage is over the programmed voltage limit.";
CM_ SG_ 2382856198 Phase_V_overcurrent_14 "Indicates an overcurrent event on Phase U. The overcurrent event is triggered when the measured phase current is over the programmed current limit.";
CM_ SG_ 2382856198 Phase_W_overvoltage_14 "Indicates an overvoltage event on Phase U. The overvoltage event is triggered when the measured phase voltage is over the programmed voltage limit.";
CM_ SG_ 2382856198 Phase_W_undervoltage_14 "Indicates an undervoltage event on Phase U. The overvoltage event is triggered when the measured phase voltage is over the programmed voltage limit.";
CM_ SG_ 2382856198 Phase_W_overcurrent_14 "Indicates an overcurrent event on Phase U. The overcurrent event is triggered when the measured phase current is over the programmed current limit.";
CM_ SG_ 2382856198 DC_undervoltage_14 "DC bus undervoltage condition. The undervoltage condition is asserted when the measured dc bus voltage is under the programmed voltage limit.";
CM_ SG_ 2382856198 DC_overvoltage_14 "DC bus overvoltage condition. The overvoltage condition is asserted when the measured dc bus voltage is over the programmed voltage limit.";
CM_ SG_ 2382856198 MOSFET_overtemperature_14 "This flag is asserted when the temperature of the MOSFET block is too high.";
CM_ SG_ 2382856198 Inductor_overtemperature_14 "This flag is asserted when the temperature of the inductor block is too high.";
CM_ SG_ 2382856198 Keep_Alive_not_served_14 "The Keep Alive feature is enabled but it was not served with the periodic message.";
CM_ SG_ 2382856198 PLL_not_locked_14 "Flag asserted when in rectifier modes, the PLL went out of lock condition";
CM_ SG_ 2382856198 Measurement_system_failure_14 "The voltages/currents measurement system is malfunctionning, and readouts are not guaranteed to be accurate.";
CM_ SG_ 2382856198 EEPROM_failure_14 "The configuration EEPROM failed to load or save the module configuration.";
CM_ SG_ 2382856195 Phase_U_14 "Phase current is the MOSFET loop current, in the branch U of the converter.";
CM_ SG_ 2382856195 Phase_V_14 "Phase current is the MOSFET loop current, in the branch V of the converter.";
CM_ SG_ 2382856195 Phase_W_14 "Phase current is the MOSFET loop current, in the branch W of the converter.";
CM_ SG_ 2382856208 Bus_current_14 "DC Bus current is possitive when current goes from input to output";
CM_ SG_ 2382856206 Phase_U_14 "Phase current is the MOSFET loop current, in the branch U of the converter.";
CM_ SG_ 2382856206 Phase_V_14 "Phase current is the MOSFET loop current, in the branch V of the converter.";
CM_ SG_ 2382856206 Phase_W_14 "Phase current is the MOSFET loop current, in the branch W of the converter.";
CM_ SG_ 2382856206 Stack_position_14 "Sender Stack position";
CM_ SG_ 2382856206 Group_ID_14 "Sender Group ID";
CM_ SG_ 2382856203 Phase_U_14 "RMS Phase current is the MOSFET loop current, in the branch U of the converter.";
CM_ SG_ 2382856203 Phase_V_14 "RMS Phase current is the MOSFET loop current, in the branch V of the converter.";
CM_ SG_ 2382856203 Phase_W_14 "RMS Phase current is the MOSFET loop current, in the branch W of the converter.";
CM_ SG_ 2382856204 Frequency_14 "Frequency of Three-Phase system";
CM_ SG_ 2382856204 Phase_14 "Phase of Three-Phase system";
CM_ SG_ 2382856197 Temp_Bridge_14 "Temperature of the MOSFET block";
CM_ SG_ 2382856197 Temp_Inductors_14 "Temperature of the inductors";
CM_ SG_ 2382856200 Phase_U_14 "The actual PWM duty cycle setpoint";
CM_ SG_ 2382856200 Phase_V_14 "The actual PWM duty cycle setpoint";
CM_ SG_ 2382856200 Phase_W_14 "The actual PWM duty cycle setpoint";
CM_ SG_ 2382856201 Current_setpoint_14 "The actual current setpoint";
CM_ SG_ 2382856201 Voltage_setpoint_14 "The actual voltage setpoint";
CM_ SG_ 2382856201 Frequency_setpoint_14 "The actual frequency setpoint";
CM_ SG_ 2382823520 Keep_Alive_Enable_14 "If set to 1, module will expect to receive this message every second repeatedly, or it will stop operation";
CM_ SG_ 2382823488 Converter_ON_14 "Enable the converter.";
CM_ SG_ 2382823488 PWM_ON_14 "Enable the PWM control mode.";
CM_ SG_ 2382823488 DC_Current_feedback_ON_14 "Enable the DC current loop";
CM_ SG_ 2382823488 AC_Current_feedback_ON_14 "Enable the AC current loop";
CM_ SG_ 2382823488 Buck_ON_14 "Enable the buck control mode.";
CM_ SG_ 2382823488 Boost_ON_14 "Enable the boost control mode.";
CM_ SG_ 2382823488 Rectifier_3ph_ON_14 "Enable the three-phase rectifier control mode.";
CM_ SG_ 2382823488 Inverter_1ph_ON_14 "Enable the single-phase inverter control mode.";
CM_ SG_ 2382823488 Rectifier_1ph_ON_14 "Enable the single-phase rectifier control mode.";
CM_ SG_ 2382823488 Boost_Neutral_ON_14 "Enable the boost control mode with neutral generation.";
CM_ SG_ 2382823488 Inverter_3ph_ON_14 "Enable the three-phase inverter control mode.";
CM_ SG_ 2382823488 Inverter_1ph_Sync_ON_14 "Single-phase inverter control mode with phase synchronization.";
CM_ SG_ 2382823488 Neutral_ON_14 "Open-loop neutral generation.";
CM_ SG_ 2382823488 Rectifier_1ph_Buck_ON_14 "Single-phase rectifier with buck on one leg.";
CM_ SG_ 2382823488 Inverter_1ph_Boost_ON_14 "Single-phase inverter with boost on one leg.";
CM_ SG_ 2382823488 Rectifier_Distributed_ON_14 "Single-phase (floating) distributed rectifier";
CM_ SG_ 2382823488 MPPT_buck_ON_14 "MPPT buck";
CM_ SG_ 2382823488 MPPT_boost_ON_14 "MPPT boost";
CM_ SG_ 2382823488 Buck_2p_float_ON_14 "Boost on L1 and L2. Floating L3 (high-impedance)";
CM_ SG_ 2382823488 Inverter_1ph_Distributed_ON_14 "Single-phase inverter mode distributed";
CM_ SG_ 2382823504 Clear_Interlock_14 "Clears the converter interlock";
CM_ SG_ 2382823504 Reset_Processor_14 "Reset the converter DSP";
CM_ SG_ 2382823504 Trip_Interlock_14 "Trip the inetrnal Interlock";
CM_ SG_ 2382823489 Reactive_current_setpoint_14 "This defines reactive current setpoint for 3-phase rectifier mode";
CM_ SG_ 2382823490 Phase_U_14 "The actual PWM duty cycle setpoint";
CM_ SG_ 2382823490 Phase_V_14 "The actual PWM duty cycle setpoint";
CM_ SG_ 2382823490 Phase_W_14 "The actual PWM duty cycle setpoint";
CM_ SG_ 2382823491 Current_setpoint_14 "Sets the output current setpoint. Active only when the current loop is enabled";
CM_ SG_ 2382823492 Voltage_setpoint_14 "Sets the output voltage setpoint. Active only when the voltage loop is enabled";
CM_ SG_ 2382823496 Frequency_setpoint_14 "Sets the frequency for single-phase and three-phase generator modes.";
CM_ SG_ 2382823497 Phase_setpoint_14 "Sets the phase for inverter control modes.";
CM_ SG_ 2382823493 Stack_position_14 "The converter position within the stack";
CM_ SG_ 2382823493 Stack_size_14 "How many PFC converters are in stack in total";
CM_ SG_ 2382823493 SN_number_14 "Unique module serial number";
CM_ SG_ 2382823472 Phase_voltage_min_14 "Minimum tolerated phase voltage";
CM_ SG_ 2382823472 Phase_voltage_max_14 "Maximum allowable phase voltage";
CM_ SG_ 2382823472 DC_voltage_min_14 "Minimum allowable dc voltage";
CM_ SG_ 2382823472 DC_voltage_max_14 "Maximum allowable dc voltage";
CM_ SG_ 2382823473 Phase_current_min_14 "Minimum allowable output current";
CM_ SG_ 2382823473 Phase_current_max_14 "Maximum allowable output current";
CM_ SG_ 2382823500 Group_ID_14 "Desired group ID for the device";
CM_ SG_ 2382856207 Group_ID_14 "Group ID of the device";
CM_ SG_ 2382823521 Factory_mode_14 "Customers MUST NOT USE this bit. If set to 1, module will enter in factory mode. ";
CM_ SG_ 2382823521 Silent_CAN_mode_14 "Customers MUST NOT USE this bit. If set to 1, module will enter in factory mode. ";
CM_ SG_ 2382823498 start_14 "Start automatic calibration. Multiplexer index must be 0!";
CM_ SG_ 2382823499 point_14 "Calibration point index.";
CM_ SG_ 2382823494 CRC_14 "Checksum of bytes 0 to 3, CRC-CCITT, corresponding to qChecksum (www.qt.io)";
CM_ SG_ 2382823495 CRC_14 "Checksum of bytes 0 to 3, CRC-CCITT, corresponding to qChecksum (www.qt.io)";
CM_ SG_ 2382856278 Current_U_High_14 "This flag is set if a hight current on U tripped the internal interlock";
CM_ SG_ 2382856278 Current_U_Low_14 "This flag is set if a low current on U tripped the internal interlock";
CM_ SG_ 2382856278 Current_V_High_14 "This flag is set if a hight current on V tripped the internal interlock";
CM_ SG_ 2382856278 Current_V_Low_14 "This flag is set if a low current on V tripped the internal interlock";
CM_ SG_ 2382856278 Current_W_High_14 "This flag is set if a hight current on W tripped the internal interlock";
CM_ SG_ 2382856278 Current_W_Low_14 "This flag is set if a low current on W tripped the internal interlock";
CM_ SG_ 2382856278 Voltage_DC_14 "This flag is set if a voltage on DC tripped the internal interlock";
CM_ SG_ 2382856278 Reboot_14 "This flag is set if a reboot tripped the internal interlock";
CM_ SG_ 2382856278 Unknown_14 "This flag the reason for the internal interlock is unknown";

BA_DEF_ BO_ "SystemMessageLongSymbol" STRING;

BA_ "SystemMessageLongSymbol" BO_ 2382823489 "AFE_Reactive_Current_Setpoint_Control_14";
BA_ "SystemMessageLongSymbol" BO_ 2382823496 "AFE_Frequency_Setpoint_Control_14";
BA_ "SystemMessageLongSymbol" BO_ 2382823536 "AFE_Rectifier_Setpoint_Control_14";
BA_ "SystemMessageLongSymbol" BO_ 2382823494 "_AFE_Calibration_Offset_Update_14";

VAL_ 2382856192 Device_type_14 7 "AFE";
VAL_ 2382856198 Protection_trip_internal_14 1 "fault";
VAL_ 2382856198 Protection_trip_external_14 1 "fault";
VAL_ 2382856198 Phase_U_overcurrent_14 1 "fault";
VAL_ 2382856198 Phase_U_overvoltage_14 1 "fault";
VAL_ 2382856198 Phase_U_undervoltage_14 1 "fault";
VAL_ 2382856198 Phase_V_overvoltage_14 1 "fault";
VAL_ 2382856198 Phase_V_undervoltage_14 1 "fault";
VAL_ 2382856198 Phase_V_overcurrent_14 1 "fault";
VAL_ 2382856198 Phase_W_overvoltage_14 1 "fault";
VAL_ 2382856198 Phase_W_undervoltage_14 1 "fault";
VAL_ 2382856198 Phase_W_overcurrent_14 1 "fault";
VAL_ 2382856198 DC_undervoltage_14 1 "fault";
VAL_ 2382856198 DC_overvoltage_14 1 "fault";
VAL_ 2382856198 MOSFET_overtemperature_14 1 "fault";
VAL_ 2382856198 Inductor_overtemperature_14 1 "fault";
VAL_ 2382856198 Keep_Alive_not_served_14 1 "fault";
VAL_ 2382856198 PLL_not_locked_14 1 "fault";
VAL_ 2382856198 NFO_14 1 "fault";
VAL_ 2382856198 Measurement_system_failure_14 1 "fault";
VAL_ 2382856198 EEPROM_failure_14 1 "fault";
VAL_ 2382856198 System_14 1 "fault";
VAL_ 2382856278 Current_U_High_14 1 "fault";
VAL_ 2382856278 Current_U_Low_14 1 "fault";
VAL_ 2382856278 Current_V_High_14 1 "fault";
VAL_ 2382856278 Current_V_Low_14 1 "fault";
VAL_ 2382856278 Current_W_High_14 1 "fault";
VAL_ 2382856278 Current_W_Low_14 1 "fault";
VAL_ 2382856278 Voltage_DC_14 1 "fault";
VAL_ 2382856278 Reboot_14 1 "fault";
VAL_ 2382856278 Unknown_14 1 "fault";
SIG_VALTYPE_ 2382856273 Current_U_14 : 1;
SIG_VALTYPE_ 2382856273 Current_V_14 : 1;
SIG_VALTYPE_ 2382856273 Current_W_14 : 1;
SIG_VALTYPE_ 2382856273 Voltage_U_14 : 1;
SIG_VALTYPE_ 2382856273 Voltage_V_14 : 1;
SIG_VALTYPE_ 2382856273 Voltage_W_14 : 1;
SIG_VALTYPE_ 2382856273 Voltage_DC_14 : 1;
SIG_VALTYPE_ 2382856274 Current_U_14 : 1;
SIG_VALTYPE_ 2382856274 Current_V_14 : 1;
SIG_VALTYPE_ 2382856274 Current_W_14 : 1;
SIG_VALTYPE_ 2382856274 Voltage_U_14 : 1;
SIG_VALTYPE_ 2382856274 Voltage_V_14 : 1;
SIG_VALTYPE_ 2382856274 Voltage_W_14 : 1;
SIG_VALTYPE_ 2382856274 Voltage_DC_14 : 1;
